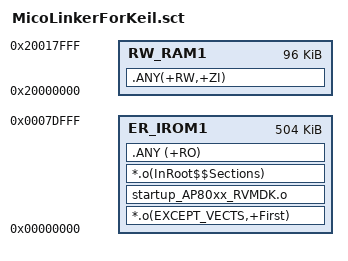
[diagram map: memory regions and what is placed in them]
; *****************************************************************************
; *** Scatter-Loading Description File generated by uVision & modify by user***
; *****************************************************************************

;LR_FLASH 0x00000000 0x800000 - 255 * 1024 {;load region size_region
LR_FLASH 0x00000000 512 * 1024 - 2 * 4 * 1024 {;load region size_region 508k for code, 2 * 4k for settings
	ER_IROM1 0x00000000 512 * 1024 - 2 * 4 * 1024 {;execution address = load address
		*.o(EXCEPT_VECTS,+First)
		startup_AP80xx_RVMDK.o
		*.o(InRoot$$Sections)
;		*.o(CACHE.4KBMEM)
;		*.o(.mach.init)
        .ANY (+RO)
	}

	;do not change the execution region name named RW_XMEM
	;you can enlarge or shrink the region size as you want
	RW_RAM1 0x20000000 0x18000 {;96KB XMEM
;		*.o (MSP,+FIRST)
		.ANY(+RW,+ZI)
	}
    ;10kRAM for BUART BUFFER
    
;	RW_RAM2 0x2001A800 0x5800 {;22KB XMEM
;		*.o (MSP,+FIRST)
;		.ANY(+RW,+ZI)
;	}
	;if you want to change the RW_XMEM room,change this 0x20010000 
	;for RW_XMEM end boundary only
	;RW_XMEM_END 0x20010000 - 4 UNINIT 4{
	;	*.o (PSP)
	;}

	;you can delete the following two execute regions if you
	;want to use the whole memory totally
	;RW_VMEM 0x20010000 UNINIT 0x8000  {;32KB VMEM
 	;}

	;RW_PMEM 0x20018000 UNINIT 0x8000 {;32KB PMEM
	;}
}

